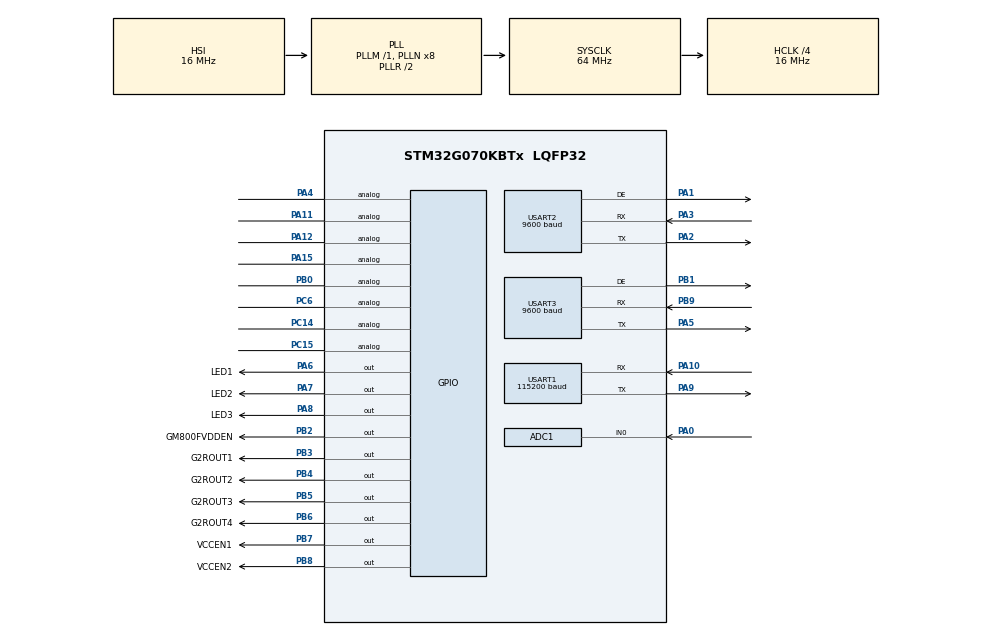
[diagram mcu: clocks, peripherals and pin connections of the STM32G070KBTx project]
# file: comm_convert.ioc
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ADC1.Channel-0\#ChannelRegularConversion=ADC_CHANNEL_0
ADC1.ClockPrescaler=ADC_CLOCK_SYNC_PCLK_DIV4
ADC1.ContinuousConvMode=ENABLE
ADC1.DMAContinuousRequests=DISABLE
ADC1.NbrOfConversionFlag=1
ADC1.OversamplingMode=DISABLE
ADC1.Rank-0\#ChannelRegularConversion=1
ADC1.SamplingTime-0\#ChannelRegularConversion=ADC_SAMPLINGTIME_COMMON_1
ADC1.SamplingTimeCommon1=ADC_SAMPLETIME_79CYCLES_5
ADC1.SamplingTimeCommon2=ADC_SAMPLETIME_79CYCLES_5
ADC1.SelectedChannel=ADC_CHANNEL_0
ADC1.master=1
IWDG.Prescaler=IWDG_PRESCALER_256
IWDG.Reload=1025
Mcu.Family=STM32G0
Mcu.Name=STM32G070KBTx
Mcu.Package=LQFP32
NVIC.TIM14_IRQn=true\:1\:0\:true\:false\:true\:true\:true\:true
NVIC.TIM16_IRQn=true\:1\:0\:true\:false\:true\:true\:true\:true
NVIC.USART1_IRQn=true\:2\:0\:true\:false\:true\:true\:true\:true
NVIC.USART2_IRQn=true\:2\:0\:true\:false\:true\:true\:true\:true
NVIC.USART3_4_IRQn=true\:2\:0\:true\:false\:true\:true\:true\:true
PA0.Mode=IN0
PA0.Signal=ADC1_IN0
PA1.Mode=Hardware Flow Control (RS485)
PA1.Signal=USART2_DE
PA10.GPIO_PuPd=GPIO_PULLUP
PA10.Mode=Asynchronous
PA10.Signal=USART1_RX
PA11\ [PA9].Signal=GPIO_Analog
PA12\ [PA10].Signal=GPIO_Analog
PA13.Mode=Serial_Wire
PA13.Signal=SYS_SWDIO
PA14-BOOT0.Mode=Serial_Wire
PA14-BOOT0.Signal=SYS_SWCLK
PA15.Signal=GPIO_Analog
PA2.Mode=Asynchronous
PA2.Signal=USART2_TX
PA3.GPIO_PuPd=GPIO_PULLUP
PA3.Mode=Asynchronous
PA3.Signal=USART2_RX
PA4.Signal=GPIO_Analog
PA5.Mode=Asynchronous
PA5.Signal=USART3_TX
PA6.GPIO_Label=LED1
PA6.PinState=GPIO_PIN_SET
PA6.Signal=GPIO_Output
PA7.GPIO_Label=LED2
PA7.PinState=GPIO_PIN_SET
PA7.Signal=GPIO_Output
PA8.GPIO_Label=LED3
PA8.PinState=GPIO_PIN_RESET
PA8.Signal=GPIO_Output
PA9.Mode=Asynchronous
PA9.Signal=USART1_TX
PB0.Signal=GPIO_Analog
PB1.Mode=Hardware Flow Control (RS485)
PB1.Signal=USART3_DE
PB2.GPIO_Label=GM800FVDDEN
PB2.Signal=GPIO_Output
PB3.GPIO_Label=G2ROUT1
PB3.Signal=GPIO_Output
PB4.GPIO_Label=G2ROUT2
PB4.Signal=GPIO_Output
PB5.GPIO_Label=G2ROUT3
PB5.Signal=GPIO_Output
PB6.GPIO_Label=G2ROUT4
PB6.Signal=GPIO_Output
PB7.GPIO_Label=VCCEN1
PB7.Signal=GPIO_Output
PB8.GPIO_Label=VCCEN2
PB8.Signal=GPIO_Output
PB9.GPIO_PuPd=GPIO_PULLUP
PB9.Mode=Asynchronous
PB9.Signal=USART3_RX
PC14-OSC32_IN\ (PC14).Signal=GPIO_Analog
PC15-OSC32_OUT\ (PC15).Signal=GPIO_Analog
PC6.Signal=GPIO_Analog
ProjectManager.HeapSize=0x200
ProjectManager.StackSize=0x400
ProjectManager.TargetToolchain=MDK-ARM V5.32
RCC.ADCFreq_Value=64000000
RCC.AHBCLKDivider=RCC_SYSCLK_DIV4
RCC.AHBFreq_Value=16000000
RCC.CortexFreq_Value=16000000
RCC.EXTERNAL_CLOCK_VALUE=48000
RCC.HCLKFreq_Value=16000000
RCC.HSE_VALUE=8000000
RCC.HSI_VALUE=16000000
RCC.LSE_VALUE=32768
RCC.SYSCLKFreq_VALUE=64000000
RCC.SYSCLKSource=RCC_SYSCLKSOURCE_PLLCLK
RCC.VCOOutputFreq_Value=128000000
TIM14.AutoReloadPreload=TIM_AUTORELOAD_PRELOAD_ENABLE
TIM14.Period=1999
TIM14.Prescaler=1599
TIM16.Period=9999
TIM16.Prescaler=1599
USART1.BaudRate=115200
USART1.DMADisableonRxErrorParam=ADVFEATURE_DMA_DISABLEONRXERROR
USART1.OverrunDisableParam=ADVFEATURE_OVERRUN_DISABLE
USART1.VirtualMode-Asynchronous=VM_ASYNC
USART2.BaudRate=9600
USART2.DMADisableonRxErrorParam=ADVFEATURE_DMA_DISABLEONRXERROR
USART2.OverrunDisableParam=ADVFEATURE_OVERRUN_DISABLE
USART2.VirtualMode-Asynchronous=VM_ASYNC
USART2.VirtualMode-Hardware\ Flow\ Control\ (RS485)=VM_ASYNC
USART3.BaudRate=9600
USART3.DMADisableonRxErrorParam=ADVFEATURE_DMA_DISABLEONRXERROR
USART3.OverrunDisableParam=ADVFEATURE_OVERRUN_DISABLE
USART3.VirtualMode-Asynchronous=VM_ASYNC
USART3.VirtualMode-Hardware\ Flow\ Control\ (RS485)=VM_ASYNC
VP_IWDG_VS_IWDG.Mode=IWDG_Activate
VP_TIM14_VS_ClockSourceINT.Mode=Enable_Timer
VP_TIM16_VS_ClockSourceINT.Mode=Enable_Timer
board=custom

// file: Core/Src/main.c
/* USER CODE BEGIN Header */
/**
  ******************************************************************************
  * @file           : main.c
  * @brief          : Main program body
  ******************************************************************************
  * @attention
  *
  * Copyright (c) 2026 STMicroelectronics.
  * All rights reserved.
  *
  * This software is licensed under terms that can be found in the LICENSE file
  * in the root directory of this software component.
  * If no LICENSE file comes with this software, it is provided AS-IS.
  *
  ******************************************************************************
  */
/* USER CODE END Header */
#include "main.h"
#include "adc.h"
#include "iwdg.h"
#include "tim.h"
#include "usart.h"
#include "gpio.h"

/* USER CODE BEGIN Includes */
#include "app_main.h"
#include "boot_config.h"
#include "bsp_system.h"
/* USER CODE END Includes */

void SystemClock_Config(void);

int main(void)
{

  /* USER CODE BEGIN 1 */
    if(BOOT_APP_ADDRESS == bsp_system_image_base())
    {
        __disable_irq();
        SCB->VTOR = BOOT_APP_ADDRESS;
        __DSB();
        __ISB();
        __set_PRIMASK(0U);
    }
  /* USER CODE END 1 */

  /* MCU Configuration--------------------------------------------------------*/

  /* Reset of all peripherals, Initializes the Flash interface and the Systick. */
  HAL_Init();

  /* Configure the system clock */
  SystemClock_Config();

  /* USER CODE BEGIN SysInit */
  if(0U == app_prepare_outputs())
  {
    Error_Handler();
  }
  /* USER CODE END SysInit */

  /* Initialize all configured peripherals */
  MX_GPIO_Init();
  MX_ADC1_Init();
  MX_USART1_UART_Init();
  MX_USART2_UART_Init();
  MX_USART3_UART_Init();
  MX_IWDG_Init();
  MX_TIM14_Init();
  MX_TIM16_Init();
  /* USER CODE BEGIN 2 */
  if(0U == app_init())
  {
    Error_Handler();
  }
  /* USER CODE END 2 */

  /* Infinite loop */
  while (1)
  {

    /* USER CODE BEGIN 3 */
    if(0U == app_task())
    {
      Error_Handler();
    }
  }
  /* USER CODE END 3 */
}

void SystemClock_Config(void)
{
  RCC_OscInitTypeDef RCC_OscInitStruct = {0};
  RCC_ClkInitTypeDef RCC_ClkInitStruct = {0};

  /** Configure the main internal regulator output voltage
  */
  HAL_PWREx_ControlVoltageScaling(PWR_REGULATOR_VOLTAGE_SCALE1);

  /** Initializes the RCC Oscillators according to the specified parameters
  * in the RCC_OscInitTypeDef structure.
  */
  RCC_OscInitStruct.OscillatorType = RCC_OSCILLATORTYPE_HSI|RCC_OSCILLATORTYPE_LSI;
  RCC_OscInitStruct.HSIState = RCC_HSI_ON;
  RCC_OscInitStruct.HSIDiv = RCC_HSI_DIV1;
  RCC_OscInitStruct.HSICalibrationValue = RCC_HSICALIBRATION_DEFAULT;
  RCC_OscInitStruct.LSIState = RCC_LSI_ON;
  RCC_OscInitStruct.PLL.PLLState = RCC_PLL_ON;
  RCC_OscInitStruct.PLL.PLLSource = RCC_PLLSOURCE_HSI;
  RCC_OscInitStruct.PLL.PLLM = RCC_PLLM_DIV1;
  RCC_OscInitStruct.PLL.PLLN = 8;
  RCC_OscInitStruct.PLL.PLLP = RCC_PLLP_DIV2;
  RCC_OscInitStruct.PLL.PLLR = RCC_PLLR_DIV2;
  if (HAL_RCC_OscConfig(&RCC_OscInitStruct) != HAL_OK)
  {
    Error_Handler();
  }

  /** Initializes the CPU, AHB and APB buses clocks
  */
  RCC_ClkInitStruct.ClockType = RCC_CLOCKTYPE_HCLK|RCC_CLOCKTYPE_SYSCLK
                              |RCC_CLOCKTYPE_PCLK1;
  RCC_ClkInitStruct.SYSCLKSource = RCC_SYSCLKSOURCE_PLLCLK;
  RCC_ClkInitStruct.AHBCLKDivider = RCC_SYSCLK_DIV4;
  RCC_ClkInitStruct.APB1CLKDivider = RCC_HCLK_DIV1;

  if (HAL_RCC_ClockConfig(&RCC_ClkInitStruct, FLASH_LATENCY_0) != HAL_OK)
  {
    Error_Handler();
  }
}

void Error_Handler(void)
{
  __disable_irq();
  while (1)
  {
  }
}
